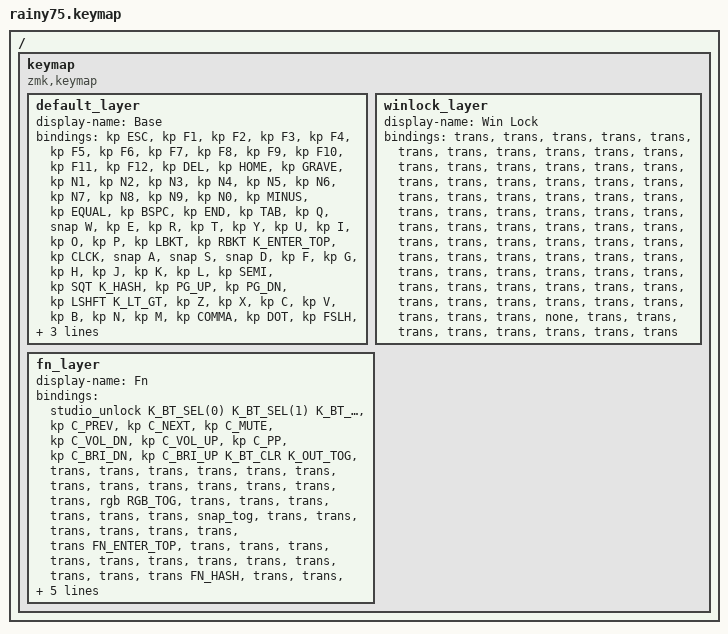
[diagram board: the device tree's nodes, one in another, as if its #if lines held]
#include <behaviors.dtsi>
#include <rainy_rgb.dtsi>
#include <rainy75_ble.dtsi>
#include <rainy_snap_tap.dtsi>
#include <dt-bindings/rainy_rgb.h>
#include <dt-bindings/zmk/keys.h>
#include <dt-bindings/zmk/bt.h>
#include <dt-bindings/zmk/outputs.h>

/* ── Physical layout: ISO (default) or ANSI ──
 * Build ANSI with `./build.sh --ansi` (it passes -DDTS_EXTRA_CPPFLAGS=-DRAINY75_ANSI
 * to the devicetree preprocessor, which is how both this keymap and the matrix
 * transform in rainy75.dts see RAINY75_ANSI). A Kconfig `#ifdef CONFIG_RAINY75_ANSI`
 * can't work here: devicetree is preprocessed before Kconfig runs, so the symbol is
 * undefined and ISO was always emitted — caught by @jaxx2104, who also verified the
 * matrix positions below on real ANSI hardware.
 *
 * ANSI vs ISO around Enter:
 *   - QWERTY-row end RC(2,13):  ISO Enter         -> ANSI Backslash
 *   - home-row slot:            ISO #~ @ RC(3,12) -> ANSI wide Enter @ RC(3,13)
 *                               (rainy75.dts swaps the matrix cell for this slot)
 *   - bottom-row RC(4,1):       ISO <> (NUBS)     -> absent on ANSI */
#ifdef RAINY75_ANSI
#define K_ENTER_TOP  &kp BSLH   /* ISO Enter (top) -> ANSI backslash */
#define K_HASH       &kp RET    /* ISO #~ (NUHS)   -> ANSI wide Enter */
#define K_LT_GT      &none      /* ISO <> (NUBS)   -> absent on ANSI */
/* Fn-layer RGB keys follow the physical Enter / backslash like the stock
 * firmware (Fn+Enter = next effect, Fn+\ = colour). */
#define FN_ENTER_TOP &rgb RGB_HUI
#define FN_HASH      &rgb RGB_EFF
#else
#define K_ENTER_TOP  &kp RET
#define K_HASH       &kp NUHS
#define K_LT_GT      &kp NUBS
#define FN_ENTER_TOP &rgb RGB_EFF
#define FN_HASH      &rgb RGB_HUI
#endif

/* ── Wired build (./build.sh --wired, -DRAINY75_WIRED) ──
 * No Bluetooth: the Fn+F1..F4 and Fn+Del slots do nothing (the &bt / &bt_sel_ble
 * behaviors are not compiled without CONFIG_ZMK_BLE). */
#ifdef RAINY75_WIRED
#define K_BT_SEL(n)  &none
#define K_OUT_TOG    &none
#define K_BT_CLR     &none
#else
#define K_BT_SEL(n)  &bt_sel_ble n
#define K_OUT_TOG    &out OUT_TOG
#define K_BT_CLR     &bt BT_CLR
#endif

/* Layer ids. The Win lock layer sits BELOW the Fn layer so Fn+LGUI still
 * reaches the toggle while the lock is active (the highest active layer wins
 * a position; the lock layer blanks LGUI). KEYMAP-COUPLED: zmk_adapter.c
 * (RRGB_LAYER_*) and overlay.c (fn_keys, snap_keys) use these positions. */
#define L_BASE    0
#define L_WINLOCK 1
#define L_FN      2

/ {
	keymap {
		compatible = "zmk,keymap";

		default_layer {
			display-name = "Base";
			/* ISO DE 75% — Layer 0
			 * ,------+----+----+----+----+----+----+----+----+----+----+----+----+----+----.
			 * | ESC  | F1 | F2 | F3 | F4 | F5 | F6 | F7 | F8 | F9 |F10 |F11 |F12 |DEL |HOME|
			 * |------+----+----+----+----+----+----+----+----+----+----+----+----+----+----|
			 * |  `   | 1  | 2  | 3  | 4  | 5  | 6  | 7  | 8  | 9  | 0  | -  | =  |BKSP|END |
			 * |------+----+----+----+----+----+----+----+----+----+----+----+----+----+----|
			 * | TAB  | Q  | W  | E  | R  | T  | Y  | U  | I  | O  | P  | [  | ]  |ENTR|    |
			 * |------+----+----+----+----+----+----+----+----+----+----+----+----+----+----|
			 * | CAPS | A  | S  | D  | F  | G  | H  | J  | K  | L  | ;  | '  | #  |PGUP|PGDN|
			 * |------+----+----+----+----+----+----+----+----+----+----+----+----+----+----|
			 * |LSHFT | <> | Z  | X  | C  | V  | B  | N  | M  | ,  | .  | /  |RSHF| UP |    |
			 * |------+----+----+----+----+----+----+----+----+----+----+----+----+----+----|
			 * |LCTRL|LGUI|LALT|              SPACE             |RALT| Fn |RCTL|LEFT|DOWN|RGHT|
			 * `------+----+----+----+----+----+----+----+----+----+----+----+----+----+----'
			 * W/A/S/D are &snap (Snap Tap: last input wins while both keys of
			 * A/D or W/S are held; Fn+T toggles it). With it off, &snap is &kp.
			 */
			bindings = <
				&kp ESC   &kp F1   &kp F2   &kp F3  &kp F4  &kp F5  &kp F6  &kp F7  &kp F8  &kp F9    &kp F10   &kp F11   &kp F12   &kp DEL   &kp HOME
				&kp GRAVE &kp N1   &kp N2   &kp N3  &kp N4  &kp N5  &kp N6  &kp N7  &kp N8  &kp N9    &kp N0    &kp MINUS &kp EQUAL &kp BSPC  &kp END
				&kp TAB   &kp Q    &snap W  &kp E   &kp R   &kp T   &kp Y   &kp U   &kp I   &kp O     &kp P     &kp LBKT  &kp RBKT  K_ENTER_TOP
				&kp CLCK  &snap A  &snap S  &snap D &kp F   &kp G   &kp H   &kp J   &kp K   &kp L     &kp SEMI  &kp SQT   K_HASH             &kp PG_UP &kp PG_DN
				&kp LSHFT K_LT_GT  &kp Z    &kp X   &kp C   &kp V   &kp B   &kp N   &kp M   &kp COMMA &kp DOT   &kp FSLH            &kp RSHFT &kp UP
				&kp LCTRL &kp LGUI &kp LALT                                          &kp SPACE &kp RALT &mo L_FN  &kp RCTRL           &kp LEFT  &kp DOWN  &kp RIGHT
			>;
		};

		winlock_layer {
			display-name = "Win Lock";
			/* Win lock — Layer 1 (toggled with Fn+LGUI, like the stock Fn+Win).
			 * Blanks the Left GUI key for gaming; everything else falls through.
			 * The LGUI LED glows dim red while the lock is on. */
			bindings = <
				&trans &trans &trans &trans &trans &trans &trans &trans &trans &trans &trans &trans &trans &trans &trans
				&trans &trans &trans &trans &trans &trans &trans &trans &trans &trans &trans &trans &trans &trans &trans
				&trans &trans &trans &trans &trans &trans &trans &trans &trans &trans &trans &trans &trans &trans
				&trans &trans &trans &trans &trans &trans &trans &trans &trans &trans &trans &trans &trans        &trans &trans
				&trans &trans &trans &trans &trans &trans &trans &trans &trans &trans &trans &trans        &trans &trans
				&trans &none  &trans                                          &trans &trans &trans &trans        &trans &trans &trans
			>;
		};

		fn_layer {
			display-name = "Fn";
			/* Fn Layer — Layer 2
			 * Fn+F1/F2/F3 = BT profile 1/2/3, also switches the output from USB to BLE
			 * Fn+F4 = Output toggle (USB/BLE)
			 * Fn+F5-F12 = Media keys
			 * Fn+ESC = Studio unlock (press to allow ZMK Studio keymap editing)
			 * Fn+T = Snap Tap on/off (W/A/S/D flash green = on, red = off; persisted)
			 * Fn+LGUI = Win key lock on/off (layer 1)
			 * Fn+Backspace = RGB toggle
			 * Fn+Enter = RGB effect cycle (ANSI: Fn+\ = hue, Fn+Enter = effect)
			 * Fn+# = RGB hue cycle
			 * Fn+↑/↓ = RGB brightness up/down
			 * Fn+←/→ = RGB speed down/up
			 * Fn+B = battery gauge
			 */
			bindings = <
				&studio_unlock K_BT_SEL(0) K_BT_SEL(1) K_BT_SEL(2) K_OUT_TOG &kp C_PREV &kp C_NEXT &kp C_MUTE &kp C_VOL_DN &kp C_VOL_UP &kp C_PP &kp C_BRI_DN &kp C_BRI_UP K_BT_CLR K_OUT_TOG
				&trans &trans &trans &trans &trans &trans &trans &trans &trans &trans &trans &trans &trans &rgb RGB_TOG &trans
				&trans &trans &trans &trans &trans &snap_tog &trans &trans &trans &trans &trans &trans &trans FN_ENTER_TOP
				&trans &trans &trans &trans &trans &trans &trans &trans &trans &trans &trans &trans FN_HASH             &trans &trans
				&trans &trans &trans &trans &trans &trans &rgb RGB_BAT &trans &trans &trans &trans &trans        &trans &rgb RGB_BRI
				&trans &tog L_WINLOCK &trans                                   &trans &trans &trans &trans        &rgb RGB_SPD &rgb RGB_BRD &rgb RGB_SPI
			>;
		};
	};
};
